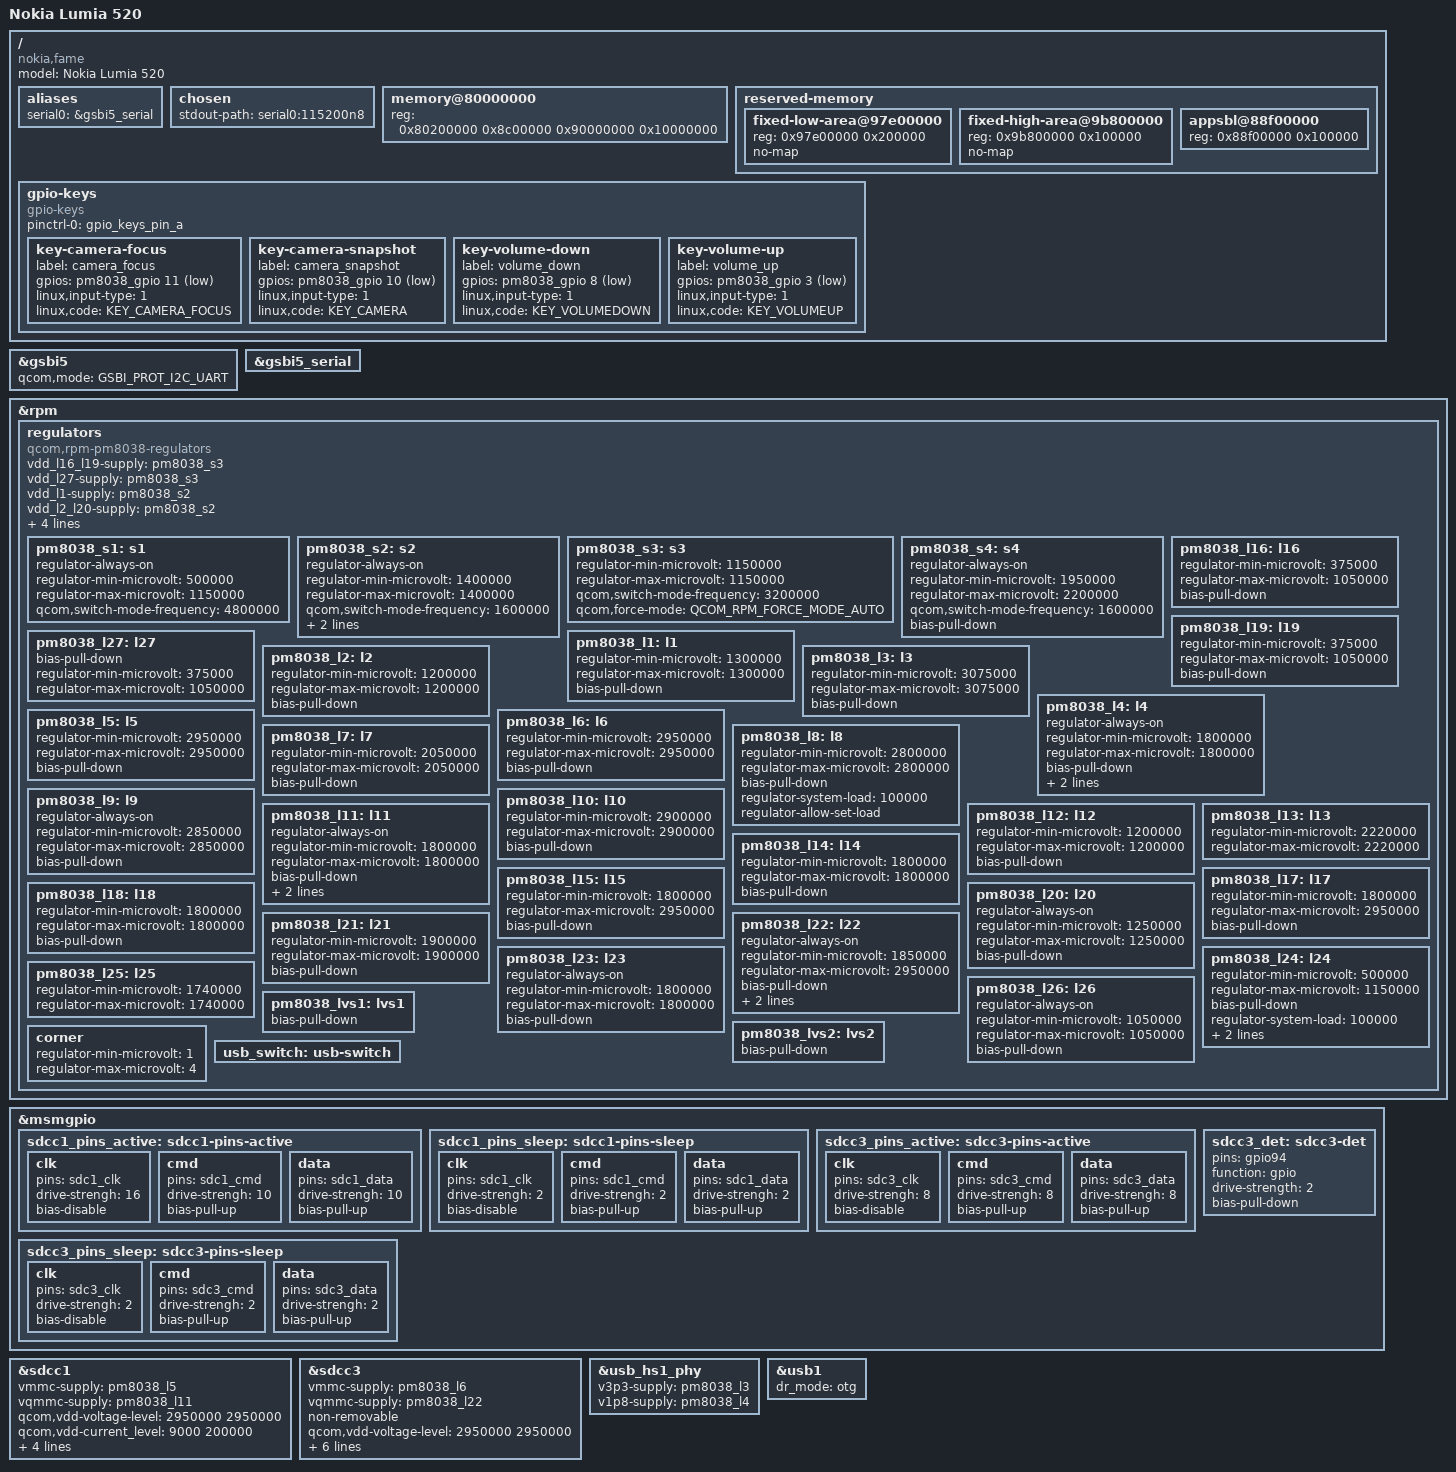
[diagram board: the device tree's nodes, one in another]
// SPDX-License-Identifier: GPL-2.0-only
#include <dt-bindings/input/input.h>
#include <dt-bindings/reset/qcom,gcc-msm8960.h>

#include "qcom-msm8930.dtsi"
#include "pm8038.dtsi"
#include <dt-bindings/gpio/gpio.h>
#include <dt-bindings/pinctrl/qcom,pmic-gpio.h>
#include <dt-bindings/input/gpio-keys.h>

/ {
	model = "Nokia Lumia 520";
	compatible = "nokia,fame", "qcom,msm8930", "qcom,msm8227";

	aliases {
		serial0 = &gsbi5_serial;
	};

	chosen {
		stdout-path = "serial0:115200n8";
	};

	memory@80000000 {
		device_type = "memory";
		reg = <0x80200000 0x8c00000 0x90000000 0x10000000>;
	};

	reserved-memory {
		#address-cells = <1>;
		#size-cells = <1>;
		ranges;

		// from downstream
		// TODO: move to msm8930.dtsi?
		fixed-low-area@97e00000 {
			reg = <0x97e00000 0x200000>;
			no-map;
		};

		fixed-high-area@9b800000 {
			reg = <0x9b800000 0x100000>;
			no-map;
		};

		// from lk
		// TODO: I'm not sure, maybe can be removed
		/*boot1@8ff00000 {
			reg = <0x8ff00000 0x100000>;
		};*/

		appsbl@88f00000 {
			reg = <0x88f00000 0x100000>;
		};
	};

	gpio-keys {
        compatible = "gpio-keys";

        pinctrl-names = "default";
        pinctrl-0 = <&gpio_keys_pin_a>;

        key-camera-focus {
            label = "camera_focus";
            gpios = <&pm8038_gpio 11 GPIO_ACTIVE_LOW>;
            linux,input-type = <1>;
            linux,code = <KEY_CAMERA_FOCUS>;
        };

        key-camera-snapshot {
            label = "camera_snapshot";
            gpios = <&pm8038_gpio 10 GPIO_ACTIVE_LOW>;
            linux,input-type = <1>;
            linux,code = <KEY_CAMERA>;
        };

        key-volume-down {
            label = "volume_down";
            gpios = <&pm8038_gpio 8 GPIO_ACTIVE_LOW>;
            linux,input-type = <1>;
            linux,code = <KEY_VOLUMEDOWN>;
        };

        key-volume-up {
            label = "volume_up";
            gpios = <&pm8038_gpio 3 GPIO_ACTIVE_LOW>;
            linux,input-type = <1>;
            linux,code = <KEY_VOLUMEUP>;
		};
    };

	/*touch_reset {
		compatible = "regulator-fixed";
		regulator-name = "touch_reset";
		gpio = <&msmgpio 52 GPIO_ACTIVE_HIGH>;
		enable-active-high;
		regulator-always-on;
	};*/
};

/*&gsbi3 {
	qcom,crci = <GSBI_CRCI_QUP>;
	qcom,mode = <GSBI_PROT_I2C>;
	status = "okay";
};

&gsbi3_i2c {
	clock-frequency = <400000>;
	qcom,src-freq = <24000000>;

	synaptics@4b {
		compatible = "syna,rmi4-i2c";
		reg = <0x4b>;

		interrupts-extended = <&msmgpio 11 IRQ_TYPE_EDGE_FALLING>;
		vdd-supply = <&pm8038_l9>; // l17
		vio-supply = <&pm8038_lvs2>; // TODO

		pinctrl-names = "default";
		pinctrl-0 = <&touch_pins>;

		#address-cells = <1>;
		#size-cells = <0>;

		rmi4-f01@1 {
			reg = <0x1>;
			syna,nosleep-mode = <1>;
		};

		rmi4-f11@11 {
			reg = <0x11>;
			syna,sensor-type = <1>;
		};
	};
};*/

&gsbi5 {
	qcom,mode = <GSBI_PROT_I2C_UART>;
	status = "okay";
};

&gsbi5_serial {
	status = "okay";
};

&rpm {
	regulators {
		compatible = "qcom,rpm-pm8038-regulators";
		/* NLDO1200 supply */
		vdd_l16_l19-supply = <&pm8038_s3>;
		vdd_l27-supply = <&pm8038_s3>;
		/* LDO supply */
		vdd_l1-supply = <&pm8038_s2>;
		vdd_l2_l20-supply = <&pm8038_s2>;
		vdd_l12_l24_l26-supply = <&pm8038_s2>;
		vdd_l7_l11_l21_l23-supply = <&pm8038_s4>;
		vdd_l25-supply = <&pm8038_l13>;
		/* LVS supply */
		vin_lvs-supply = <&pm8038_l11>;

		/* SMPS */
		pm8038_s1: s1 {
			regulator-always-on;
			regulator-min-microvolt = <500000>;
			regulator-max-microvolt = <1150000>;
			qcom,switch-mode-frequency = <4800000>;
		};

		pm8038_s2: s2 {
		    regulator-always-on;
			regulator-min-microvolt = <1400000>;
			regulator-max-microvolt = <1400000>;
			qcom,switch-mode-frequency = <1600000>;
			bias-pull-down;

			qcom,force-mode = <QCOM_RPM_FORCE_MODE_LPM>;
		};

		pm8038_s3: s3 {
			regulator-min-microvolt = <1150000>;
			regulator-max-microvolt = <1150000>;
			qcom,switch-mode-frequency = <3200000>;
			qcom,force-mode = <QCOM_RPM_FORCE_MODE_AUTO>;
		};

		pm8038_s4: s4 {
			regulator-always-on;
			regulator-min-microvolt = <1950000>;
			regulator-max-microvolt = <2200000>;
			qcom,switch-mode-frequency = <1600000>;
			bias-pull-down;
		};

		// S5 and S6 are CPU0 & CPU1 SAW

		/* NLDO1200 */
		pm8038_l16: l16 {
			regulator-min-microvolt = <375000>;
			regulator-max-microvolt = <1050000>;
			bias-pull-down;
		};

		pm8038_l19: l19 {
			regulator-min-microvolt = <375000>;
			regulator-max-microvolt = <1050000>;
			bias-pull-down;
		};

		pm8038_l27: l27 {
			bias-pull-down;
			regulator-min-microvolt = <375000>;
			regulator-max-microvolt = <1050000>;
		};

		/* LDO */
		pm8038_l1: l1 {
			regulator-min-microvolt = <1300000>;
			regulator-max-microvolt = <1300000>;
			bias-pull-down;
		};

		pm8038_l2: l2 {
			regulator-min-microvolt = <1200000>;
			regulator-max-microvolt = <1200000>;
			bias-pull-down;
		};

		pm8038_l3: l3 {
			regulator-min-microvolt = <3075000>;
			regulator-max-microvolt = <3075000>;
			bias-pull-down;
		};

		pm8038_l4: l4 {
			regulator-always-on;
			regulator-min-microvolt = <1800000>;
			regulator-max-microvolt = <1800000>;
			bias-pull-down;

			regulator-system-load = <100000>;
            regulator-allow-set-load;
		};

		pm8038_l5: l5 {
			regulator-min-microvolt = <2950000>;
			regulator-max-microvolt = <2950000>;
			bias-pull-down;
		};

		pm8038_l6: l6 {
			regulator-min-microvolt = <2950000>;
			regulator-max-microvolt = <2950000>;
			bias-pull-down;
		};

		pm8038_l7: l7 {
			regulator-min-microvolt = <2050000>;
			regulator-max-microvolt = <2050000>;
			bias-pull-down;
		};

		pm8038_l8: l8 {
			regulator-min-microvolt = <2800000>;
			regulator-max-microvolt = <2800000>;
			bias-pull-down;

			regulator-system-load = <100000>;
            regulator-allow-set-load;
		};

		pm8038_l9: l9 {
		    regulator-always-on;
			regulator-min-microvolt = <2850000>;
			regulator-max-microvolt = <2850000>;
			bias-pull-down;
		};

		pm8038_l10: l10 {
			regulator-min-microvolt = <2900000>;
			regulator-max-microvolt = <2900000>;
			bias-pull-down;
		};

		pm8038_l11: l11 {
		    regulator-always-on;
			regulator-min-microvolt = <1800000>;
			regulator-max-microvolt = <1800000>;
			bias-pull-down;

			regulator-system-load = <100000>;
            regulator-allow-set-load;
		};

		pm8038_l12: l12 {
			regulator-min-microvolt = <1200000>;
			regulator-max-microvolt = <1200000>;
			bias-pull-down;
		};

		pm8038_l13: l13 {
            regulator-min-microvolt = <2220000>;
            regulator-max-microvolt = <2220000>;
		};

		pm8038_l14: l14 {
			regulator-min-microvolt = <1800000>;
			regulator-max-microvolt = <1800000>;
			bias-pull-down;
		};

		pm8038_l15: l15 {
			regulator-min-microvolt = <1800000>;
			regulator-max-microvolt = <2950000>;
			bias-pull-down;
		};

		pm8038_l17: l17 {
			regulator-min-microvolt = <1800000>;
			regulator-max-microvolt = <2950000>;
			bias-pull-down;
		};

		pm8038_l18: l18 {
			regulator-min-microvolt = <1800000>;
			regulator-max-microvolt = <1800000>;
			bias-pull-down;
		};

		pm8038_l20: l20 {
		    regulator-always-on;
			regulator-min-microvolt = <1250000>;
			regulator-max-microvolt = <1250000>;
			bias-pull-down;

			/*regulator-system-load = <100000>;
            regulator-allow-set-load;*/
		};

		pm8038_l21: l21 {
			regulator-min-microvolt = <1900000>;
			regulator-max-microvolt = <1900000>;
			bias-pull-down;
		};

		pm8038_l22: l22 {
		    regulator-always-on;
			regulator-min-microvolt = <1850000>;
			regulator-max-microvolt = <2950000>;
			bias-pull-down;

			regulator-system-load = <100000>;
            regulator-allow-set-load;
		};

		pm8038_l23: l23 {
			regulator-always-on;
			regulator-min-microvolt = <1800000>;
			regulator-max-microvolt = <1800000>;
			bias-pull-down;
		};

		pm8038_l24: l24 {
			regulator-min-microvolt = <500000>;
			regulator-max-microvolt = <1150000>;
			bias-pull-down;

			regulator-system-load = <100000>;
            regulator-allow-set-load;

			system-critical-regulator;
		};

		pm8038_l25: l25 {
			regulator-min-microvolt = <1740000>;
			regulator-max-microvolt = <1740000>;
		};

		pm8038_l26: l26 {
			regulator-always-on;
			regulator-min-microvolt = <1050000>;
			regulator-max-microvolt = <1050000>;
			bias-pull-down;

			// TODO: in downstream this seems to be enabled
			// but here it causes reboot
			/*regulator-system-load = <100000>;
            regulator-allow-set-load;*/
		};

		/* LVS */
		pm8038_lvs1: lvs1 {
			bias-pull-down;
		};

		pm8038_lvs2: lvs2 {
			bias-pull-down;
		};

		corner {
            // something like this
            regulator-min-microvolt = <1>;
            regulator-max-microvolt = <4>;
        };

		usb_switch: usb-switch {}; // TODO
	};
};

&msmgpio {
	sdcc1_pins_active: sdcc1-pins-active {
		clk {
			pins = "sdc1_clk";
			drive-strengh = <16>;
			bias-disable;
		};

		cmd {
			pins = "sdc1_cmd";
			drive-strengh = <10>;
			bias-pull-up;
		};

		data {
			pins = "sdc1_data";
			drive-strengh = <10>;
			bias-pull-up;
		};
	};

	sdcc1_pins_sleep: sdcc1-pins-sleep {
		clk {
			pins = "sdc1_clk";
			drive-strengh = <2>;
			bias-disable;
		};

		cmd {
			pins = "sdc1_cmd";
			drive-strengh = <2>;
			bias-pull-up;
		};

		data {
			pins = "sdc1_data";
			drive-strengh = <2>;
			bias-pull-up;
		};
	};

	sdcc3_pins_active: sdcc3-pins-active {
		clk {
			pins = "sdc3_clk";
			drive-strengh = <8>;
			bias-disable;
		};

		cmd {
			pins = "sdc3_cmd";
			drive-strengh = <8>;
			bias-pull-up;
		};

		data {
			pins = "sdc3_data";
			drive-strengh = <8>;
			bias-pull-up;
		};
	};

	sdcc3_pins_sleep: sdcc3-pins-sleep {
		clk {
			pins = "sdc3_clk";
			drive-strengh = <2>;
			bias-disable;
		};

		cmd {
			pins = "sdc3_cmd";
			drive-strengh = <2>;
			bias-pull-up;
		};

		data {
			pins = "sdc3_data";
			drive-strengh = <2>;
			bias-pull-up;
		};
	};

	sdcc3_det: sdcc3-det {
		pins = "gpio94";
		function = "gpio";
		drive-strength = <2>;
		bias-pull-down;
	};

	/*touch_pins: touch_pins {
		reset {
			pins = "gpio52";
			function = "gpio";
			drive-strength = <6>;
			bias-pull-up;
		};

		irq {
			pins = "gpio11";
			function = "gpio";
			drive-strength = <8>;
			bias-pull-up;
		};
	};*/
};

/* eMMC */
&sdcc1 {
	vmmc-supply = <&pm8038_l5>;
	vqmmc-supply = <&pm8038_l11>;

	qcom,vdd-voltage-level = <2950000 2950000>;
	qcom,vdd-current_level = <9000 200000>;
	qcom,vdd-always-on;
	qcom,vdd-lpm_sup;

	qcom,vdd-io-voltage-level = <1800000 1800000>;
	qcom,vdd-io-current_level = <0 200000>; // no lpm for vdd-io
	// The SoC with 1.2 or higher revision doesn't require this
	// Same applies to sdcc3
	//qcom,vdd-io-always-on;

	status = "okay";
};

/* SD card */
&sdcc3 {
	vmmc-supply = <&pm8038_l6>;
	vqmmc-supply = <&pm8038_l22>;

	non-removable;

	// Detection works,
	// but we get DMA and I/O errors
	// I did some debugging and seems it stuck on invalid start bit
	// downstream also spams with I/O error and busy device,
	// so I don't know how to fix it

	qcom,vdd-voltage-level = <2950000 2950000>;
	qcom,vdd-current_level = <9000 800000>;
	qcom,vdd-always-on; // I guess
	qcom,vdd-lpm_sup;


	qcom,vdd-io-voltage-level = <1850000 2950000>;
	qcom,vdd-io-current_level = <2000 16000>;
	//qcom,vdd-io-always-on;
	qcom,vdd-io-lpm_sup;

	status = "okay";
};

&usb_hs1_phy {
	v3p3-supply = <&pm8038_l3>;
	v1p8-supply = <&pm8038_l4>;
	//qcom,init-seq = /bits/ 8 <0x44 0x80 0x38 0x81 0x3C 0x82 0x13 0x83>; // TODO -1?
};

&usb1 {
	dr_mode = "otg";
	status = "okay";
};
